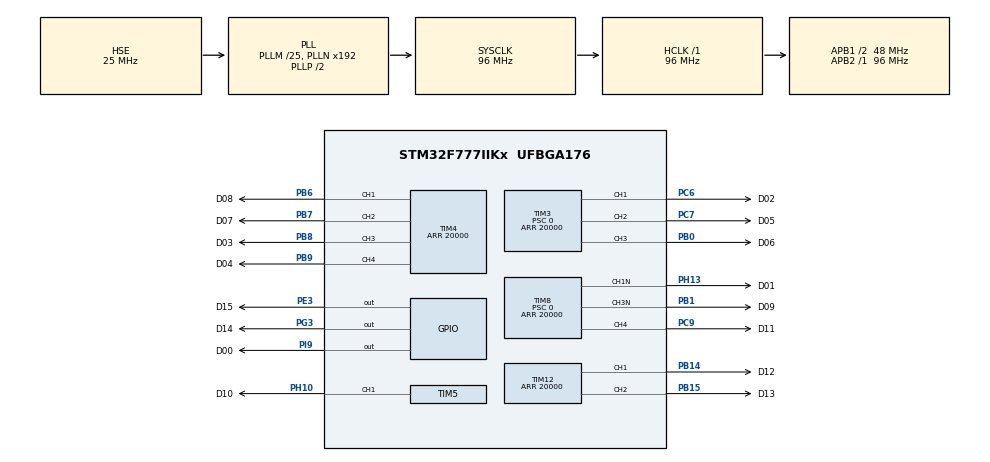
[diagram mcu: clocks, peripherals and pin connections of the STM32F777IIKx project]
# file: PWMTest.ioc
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Mcu.Family=STM32F7
Mcu.Name=STM32F777IIKx
Mcu.Package=UFBGA176
NVIC.PriorityGroup=NVIC_PRIORITYGROUP_4
PB0.GPIO_Label=D06
PB0.GPIO_Speed=GPIO_SPEED_FREQ_VERY_HIGH
PB0.Signal=S_TIM3_CH3
PB1.GPIO_Label=D09
PB1.GPIO_Speed=GPIO_SPEED_FREQ_VERY_HIGH
PB1.Mode=PWM Generation3 CH3N
PB1.Signal=TIM8_CH3N
PB14.GPIO_Label=D12
PB14.GPIO_Speed=GPIO_SPEED_FREQ_VERY_HIGH
PB14.Signal=S_TIM12_CH1
PB15.GPIO_Label=D13
PB15.GPIO_Speed=GPIO_SPEED_FREQ_VERY_HIGH
PB15.Signal=S_TIM12_CH2
PB6.GPIO_Label=D08
PB6.GPIO_Speed=GPIO_SPEED_FREQ_VERY_HIGH
PB6.Signal=S_TIM4_CH1
PB7.GPIO_Label=D07
PB7.GPIO_Speed=GPIO_SPEED_FREQ_VERY_HIGH
PB7.Signal=S_TIM4_CH2
PB8.GPIO_Label=D03
PB8.GPIO_Speed=GPIO_SPEED_FREQ_VERY_HIGH
PB8.Signal=S_TIM4_CH3
PB9.GPIO_Label=D04
PB9.GPIO_Speed=GPIO_SPEED_FREQ_VERY_HIGH
PB9.Signal=S_TIM4_CH4
PC6.GPIO_Label=D02
PC6.GPIO_Speed=GPIO_SPEED_FREQ_VERY_HIGH
PC6.Signal=S_TIM3_CH1
PC7.GPIO_Label=D05
PC7.GPIO_Speed=GPIO_SPEED_FREQ_VERY_HIGH
PC7.Signal=S_TIM3_CH2
PC9.GPIO_Label=D11
PC9.GPIO_Speed=GPIO_SPEED_FREQ_VERY_HIGH
PC9.Signal=S_TIM8_CH4
PE3.GPIO_Label=D15
PE3.GPIO_Speed=GPIO_SPEED_FREQ_VERY_HIGH
PE3.Signal=GPIO_Output
PG3.GPIO_Label=D14
PG3.GPIO_Speed=GPIO_SPEED_FREQ_VERY_HIGH
PG3.Signal=GPIO_Output
PH0/OSC_IN.Mode=HSE-External-Oscillator
PH0/OSC_IN.Signal=RCC_OSC_IN
PH1/OSC_OUT.Mode=HSE-External-Oscillator
PH1/OSC_OUT.Signal=RCC_OSC_OUT
PH10.GPIO_Label=D10
PH10.GPIO_Speed=GPIO_SPEED_FREQ_VERY_HIGH
PH10.Signal=S_TIM5_CH1
PH13.GPIO_Label=D01
PH13.GPIO_Speed=GPIO_SPEED_FREQ_VERY_HIGH
PH13.Mode=PWM Generation1 CH1N
PH13.Signal=TIM8_CH1N
PI9.GPIO_Label=D00
PI9.GPIO_Speed=GPIO_SPEED_FREQ_VERY_HIGH
PI9.Signal=GPIO_Output
ProjectManager.HeapSize=0x200
ProjectManager.StackSize=0x400
ProjectManager.TargetToolchain=STM32CubeIDE
RCC.AHBFreq_Value=96000000
RCC.APB1CLKDivider=RCC_HCLK_DIV2
RCC.APB1Freq_Value=48000000
RCC.APB1TimFreq_Value=96000000
RCC.APB2Freq_Value=96000000
RCC.APB2TimFreq_Value=96000000
RCC.CortexFreq_Value=96000000
RCC.HCLKFreq_Value=96000000
RCC.HSE_VALUE=25000000
RCC.HSI_VALUE=16000000
RCC.LSE_VALUE=32768
RCC.PLLM=25
RCC.PLLSourceVirtual=RCC_PLLSOURCE_HSE
RCC.SYSCLKFreq_VALUE=96000000
RCC.SYSCLKSource=RCC_SYSCLKSOURCE_PLLCLK
RCC.USBFreq_Value=96000000
RCC.VCOOutputFreq_Value=192000000
SH.S_TIM12_CH1.0=TIM12_CH1,PWM Generation1 CH1
SH.S_TIM12_CH2.0=TIM12_CH2,PWM Generation2 CH2
SH.S_TIM3_CH1.0=TIM3_CH1,PWM Generation1 CH1
SH.S_TIM3_CH2.0=TIM3_CH2,PWM Generation2 CH2
SH.S_TIM3_CH3.0=TIM3_CH3,PWM Generation3 CH3
SH.S_TIM4_CH1.0=TIM4_CH1,PWM Generation1 CH1
SH.S_TIM4_CH2.0=TIM4_CH2,PWM Generation2 CH2
SH.S_TIM4_CH3.0=TIM4_CH3,PWM Generation3 CH3
SH.S_TIM4_CH4.0=TIM4_CH4,PWM Generation4 CH4
SH.S_TIM5_CH1.0=TIM5_CH1,PWM Generation1 CH1
SH.S_TIM8_CH4.0=TIM8_CH4,PWM Generation4 CH4
TIM12.Channel-PWM\ Generation1\ CH1=TIM_CHANNEL_1
TIM12.Channel-PWM\ Generation2\ CH2=TIM_CHANNEL_2
TIM12.Period=20000
TIM12.Pulse-PWM\ Generation1\ CH1=13000
TIM12.Pulse-PWM\ Generation2\ CH2=14000
TIM3.AutoReloadPreload=TIM_AUTORELOAD_PRELOAD_DISABLE
TIM3.Channel-PWM\ Generation1\ CH1=TIM_CHANNEL_1
TIM3.Channel-PWM\ Generation2\ CH2=TIM_CHANNEL_2
TIM3.Channel-PWM\ Generation3\ CH3=TIM_CHANNEL_3
TIM3.Period=20000
TIM3.Prescaler=0
TIM3.Pulse-PWM\ Generation1\ CH1=3000
TIM3.Pulse-PWM\ Generation2\ CH2=6000
TIM3.Pulse-PWM\ Generation3\ CH3=7000
TIM4.Channel-PWM\ Generation1\ CH1=TIM_CHANNEL_1
TIM4.Channel-PWM\ Generation2\ CH2=TIM_CHANNEL_2
TIM4.Channel-PWM\ Generation3\ CH3=TIM_CHANNEL_3
TIM4.Channel-PWM\ Generation4\ CH4=TIM_CHANNEL_4
TIM4.Period=20000
TIM4.Pulse-PWM\ Generation1\ CH1=9000
TIM4.Pulse-PWM\ Generation2\ CH2=8000
TIM4.Pulse-PWM\ Generation3\ CH3=4000
TIM4.Pulse-PWM\ Generation4\ CH4=5000
TIM5.Channel-PWM\ Generation1\ CH1=TIM_CHANNEL_1
TIM5.Period=20000
TIM5.Pulse-PWM\ Generation1\ CH1=11000
TIM8.Channel-PWM\ Generation1\ CH1N=TIM_CHANNEL_1
TIM8.Channel-PWM\ Generation3\ CH3N=TIM_CHANNEL_3
TIM8.Channel-PWM\ Generation4\ CH4=TIM_CHANNEL_4
TIM8.Period=20000
TIM8.Prescaler=0
TIM8.Pulse-PWM\ Generation1\ CH1N=2000
TIM8.Pulse-PWM\ Generation3\ CH3N=10000
TIM8.Pulse-PWM\ Generation4\ CH4=12000
VP_TIM3_VS_ClockSourceINT.Mode=Internal
board=custom

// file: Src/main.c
/* USER CODE BEGIN Header */
/**
  ******************************************************************************
  * @file           : main.c
  * @brief          : Main program body
  ******************************************************************************
  ** This notice applies to any and all portions of this file
  * that are not between comment pairs USER CODE BEGIN and
  * USER CODE END. Other portions of this file, whether
  * inserted by the user or by software development tools
  * are owned by their respective copyright owners.
  *
  * COPYRIGHT(c) 2019 STMicroelectronics
  *
  * Redistribution and use in source and binary forms, with or without modification,
  * are permitted provided that the following conditions are met:
  *   1. Redistributions of source code must retain the above copyright notice,
  *      this list of conditions and the following disclaimer.
  *   2. Redistributions in binary form must reproduce the above copyright notice,
  *      this list of conditions and the following disclaimer in the documentation
  *      and/or other materials provided with the distribution.
  *   3. Neither the name of STMicroelectronics nor the names of its contributors
  *      may be used to endorse or promote products derived from this software
  *      without specific prior written permission.
  *
  * THIS SOFTWARE IS PROVIDED BY THE COPYRIGHT HOLDERS AND CONTRIBUTORS "AS IS"
  * AND ANY EXPRESS OR IMPLIED WARRANTIES, INCLUDING, BUT NOT LIMITED TO, THE
  * IMPLIED WARRANTIES OF MERCHANTABILITY AND FITNESS FOR A PARTICULAR PURPOSE ARE
  * DISCLAIMED. IN NO EVENT SHALL THE COPYRIGHT HOLDER OR CONTRIBUTORS BE LIABLE
  * FOR ANY DIRECT, INDIRECT, INCIDENTAL, SPECIAL, EXEMPLARY, OR CONSEQUENTIAL
  * DAMAGES (INCLUDING, BUT NOT LIMITED TO, PROCUREMENT OF SUBSTITUTE GOODS OR
  * SERVICES; LOSS OF USE, DATA, OR PROFITS; OR BUSINESS INTERRUPTION) HOWEVER
  * CAUSED AND ON ANY THEORY OF LIABILITY, WHETHER IN CONTRACT, STRICT LIABILITY,
  * OR TORT (INCLUDING NEGLIGENCE OR OTHERWISE) ARISING IN ANY WAY OUT OF THE USE
  * OF THIS SOFTWARE, EVEN IF ADVISED OF THE POSSIBILITY OF SUCH DAMAGE.
  *
  ******************************************************************************
  */
/* USER CODE END Header */

#include "main.h"

TIM_HandleTypeDef htim3;
TIM_HandleTypeDef htim4;
TIM_HandleTypeDef htim5;
TIM_HandleTypeDef htim8;
TIM_HandleTypeDef htim12;

void SystemClock_Config(void);
static void MX_GPIO_Init(void);
static void MX_TIM3_Init(void);
static void MX_TIM4_Init(void);
static void MX_TIM5_Init(void);
static void MX_TIM8_Init(void);
static void MX_TIM12_Init(void);

int main(void)
{

  /* MCU Configuration--------------------------------------------------------*/

  /* Reset of all peripherals, Initializes the Flash interface and the Systick. */
  HAL_Init();

  /* Configure the system clock */
  SystemClock_Config();

  /* Initialize all configured peripherals */
  MX_GPIO_Init();
  MX_TIM3_Init();
  MX_TIM4_Init();
  MX_TIM5_Init();
  MX_TIM8_Init();
  MX_TIM12_Init();
  /* USER CODE BEGIN 2 */

  HAL_TIM_PWM_Start(&htim3, TIM_CHANNEL_1);       //  D02
  HAL_TIM_PWM_Start(&htim3, TIM_CHANNEL_2);       //  D05
  HAL_TIM_PWM_Start(&htim3, TIM_CHANNEL_3);       //  D06

  HAL_TIM_PWM_Start(&htim4, TIM_CHANNEL_1);       //  D08
  HAL_TIM_PWM_Start(&htim4, TIM_CHANNEL_2);       //  D07
  HAL_TIM_PWM_Start(&htim4, TIM_CHANNEL_3);       //  D03
  HAL_TIM_PWM_Start(&htim4, TIM_CHANNEL_4);       //  D04

  HAL_TIM_PWM_Start(&htim5, TIM_CHANNEL_1);       //  D10

  HAL_TIMEx_PWMN_Start(&htim8, TIM_CHANNEL_1);    //  D01
  HAL_TIMEx_PWMN_Start(&htim8, TIM_CHANNEL_3);    //  D09
  HAL_TIM_PWM_Start(&htim8, TIM_CHANNEL_4);       //  D11

  HAL_TIM_PWM_Start(&htim12, TIM_CHANNEL_1);      //  D12
  HAL_TIM_PWM_Start(&htim12, TIM_CHANNEL_2);      //  D13

  /* USER CODE END 2 */

  /* Infinite loop */
  while (1)
  {

  }
}

void SystemClock_Config(void)
{
  RCC_OscInitTypeDef RCC_OscInitStruct = {0};
  RCC_ClkInitTypeDef RCC_ClkInitStruct = {0};

  /** Configure the main internal regulator output voltage
  */
  __HAL_RCC_PWR_CLK_ENABLE();
  __HAL_PWR_VOLTAGESCALING_CONFIG(PWR_REGULATOR_VOLTAGE_SCALE3);
  /** Initializes the CPU, AHB and APB busses clocks
  */
  RCC_OscInitStruct.OscillatorType = RCC_OSCILLATORTYPE_HSE;
  RCC_OscInitStruct.HSEState = RCC_HSE_ON;
  RCC_OscInitStruct.PLL.PLLState = RCC_PLL_ON;
  RCC_OscInitStruct.PLL.PLLSource = RCC_PLLSOURCE_HSE;
  RCC_OscInitStruct.PLL.PLLM = 25;
  RCC_OscInitStruct.PLL.PLLN = 192;
  RCC_OscInitStruct.PLL.PLLP = RCC_PLLP_DIV2;
  RCC_OscInitStruct.PLL.PLLQ = 2;
  if (HAL_RCC_OscConfig(&RCC_OscInitStruct) != HAL_OK)
  {
    Error_Handler();
  }
  /** Activate the Over-Drive mode
  */
  if (HAL_PWREx_EnableOverDrive() != HAL_OK)
  {
    Error_Handler();
  }
  /** Initializes the CPU, AHB and APB busses clocks
  */
  RCC_ClkInitStruct.ClockType = RCC_CLOCKTYPE_HCLK|RCC_CLOCKTYPE_SYSCLK
                              |RCC_CLOCKTYPE_PCLK1|RCC_CLOCKTYPE_PCLK2;
  RCC_ClkInitStruct.SYSCLKSource = RCC_SYSCLKSOURCE_PLLCLK;
  RCC_ClkInitStruct.AHBCLKDivider = RCC_SYSCLK_DIV1;
  RCC_ClkInitStruct.APB1CLKDivider = RCC_HCLK_DIV2;
  RCC_ClkInitStruct.APB2CLKDivider = RCC_HCLK_DIV1;

  if (HAL_RCC_ClockConfig(&RCC_ClkInitStruct, FLASH_LATENCY_3) != HAL_OK)
  {
    Error_Handler();
  }
}

static void MX_TIM3_Init(void)
{

  TIM_ClockConfigTypeDef sClockSourceConfig = {0};
  TIM_MasterConfigTypeDef sMasterConfig = {0};
  TIM_OC_InitTypeDef sConfigOC = {0};

  htim3.Instance = TIM3;
  htim3.Init.Prescaler = 0;
  htim3.Init.CounterMode = TIM_COUNTERMODE_UP;
  htim3.Init.Period = 20000;
  htim3.Init.ClockDivision = TIM_CLOCKDIVISION_DIV1;
  htim3.Init.AutoReloadPreload = TIM_AUTORELOAD_PRELOAD_DISABLE;
  if (HAL_TIM_Base_Init(&htim3) != HAL_OK)
  {
    Error_Handler();
  }
  sClockSourceConfig.ClockSource = TIM_CLOCKSOURCE_INTERNAL;
  if (HAL_TIM_ConfigClockSource(&htim3, &sClockSourceConfig) != HAL_OK)
  {
    Error_Handler();
  }
  if (HAL_TIM_PWM_Init(&htim3) != HAL_OK)
  {
    Error_Handler();
  }
  sMasterConfig.MasterOutputTrigger = TIM_TRGO_RESET;
  sMasterConfig.MasterSlaveMode = TIM_MASTERSLAVEMODE_DISABLE;
  if (HAL_TIMEx_MasterConfigSynchronization(&htim3, &sMasterConfig) != HAL_OK)
  {
    Error_Handler();
  }
  sConfigOC.OCMode = TIM_OCMODE_PWM1;
  sConfigOC.Pulse = 3000;
  sConfigOC.OCPolarity = TIM_OCPOLARITY_HIGH;
  sConfigOC.OCFastMode = TIM_OCFAST_DISABLE;
  if (HAL_TIM_PWM_ConfigChannel(&htim3, &sConfigOC, TIM_CHANNEL_1) != HAL_OK)
  {
    Error_Handler();
  }
  sConfigOC.Pulse = 6000;
  if (HAL_TIM_PWM_ConfigChannel(&htim3, &sConfigOC, TIM_CHANNEL_2) != HAL_OK)
  {
    Error_Handler();
  }
  sConfigOC.Pulse = 7000;
  if (HAL_TIM_PWM_ConfigChannel(&htim3, &sConfigOC, TIM_CHANNEL_3) != HAL_OK)
  {
    Error_Handler();
  }
  HAL_TIM_MspPostInit(&htim3);

}

static void MX_TIM4_Init(void)
{

  TIM_MasterConfigTypeDef sMasterConfig = {0};
  TIM_OC_InitTypeDef sConfigOC = {0};

  htim4.Instance = TIM4;
  htim4.Init.Prescaler = 0;
  htim4.Init.CounterMode = TIM_COUNTERMODE_UP;
  htim4.Init.Period = 20000;
  htim4.Init.ClockDivision = TIM_CLOCKDIVISION_DIV1;
  htim4.Init.AutoReloadPreload = TIM_AUTORELOAD_PRELOAD_DISABLE;
  if (HAL_TIM_PWM_Init(&htim4) != HAL_OK)
  {
    Error_Handler();
  }
  sMasterConfig.MasterOutputTrigger = TIM_TRGO_RESET;
  sMasterConfig.MasterSlaveMode = TIM_MASTERSLAVEMODE_DISABLE;
  if (HAL_TIMEx_MasterConfigSynchronization(&htim4, &sMasterConfig) != HAL_OK)
  {
    Error_Handler();
  }
  sConfigOC.OCMode = TIM_OCMODE_PWM1;
  sConfigOC.Pulse = 9000;
  sConfigOC.OCPolarity = TIM_OCPOLARITY_HIGH;
  sConfigOC.OCFastMode = TIM_OCFAST_DISABLE;
  if (HAL_TIM_PWM_ConfigChannel(&htim4, &sConfigOC, TIM_CHANNEL_1) != HAL_OK)
  {
    Error_Handler();
  }
  sConfigOC.Pulse = 8000;
  if (HAL_TIM_PWM_ConfigChannel(&htim4, &sConfigOC, TIM_CHANNEL_2) != HAL_OK)
  {
    Error_Handler();
  }
  sConfigOC.Pulse = 4000;
  if (HAL_TIM_PWM_ConfigChannel(&htim4, &sConfigOC, TIM_CHANNEL_3) != HAL_OK)
  {
    Error_Handler();
  }
  sConfigOC.Pulse = 5000;
  if (HAL_TIM_PWM_ConfigChannel(&htim4, &sConfigOC, TIM_CHANNEL_4) != HAL_OK)
  {
    Error_Handler();
  }
  HAL_TIM_MspPostInit(&htim4);

}

static void MX_TIM5_Init(void)
{

  TIM_MasterConfigTypeDef sMasterConfig = {0};
  TIM_OC_InitTypeDef sConfigOC = {0};

  htim5.Instance = TIM5;
  htim5.Init.Prescaler = 0;
  htim5.Init.CounterMode = TIM_COUNTERMODE_UP;
  htim5.Init.Period = 20000;
  htim5.Init.ClockDivision = TIM_CLOCKDIVISION_DIV1;
  htim5.Init.AutoReloadPreload = TIM_AUTORELOAD_PRELOAD_DISABLE;
  if (HAL_TIM_PWM_Init(&htim5) != HAL_OK)
  {
    Error_Handler();
  }
  sMasterConfig.MasterOutputTrigger = TIM_TRGO_RESET;
  sMasterConfig.MasterSlaveMode = TIM_MASTERSLAVEMODE_DISABLE;
  if (HAL_TIMEx_MasterConfigSynchronization(&htim5, &sMasterConfig) != HAL_OK)
  {
    Error_Handler();
  }
  sConfigOC.OCMode = TIM_OCMODE_PWM1;
  sConfigOC.Pulse = 11000;
  sConfigOC.OCPolarity = TIM_OCPOLARITY_HIGH;
  sConfigOC.OCFastMode = TIM_OCFAST_DISABLE;
  if (HAL_TIM_PWM_ConfigChannel(&htim5, &sConfigOC, TIM_CHANNEL_1) != HAL_OK)
  {
    Error_Handler();
  }
  HAL_TIM_MspPostInit(&htim5);

}

static void MX_TIM8_Init(void)
{

  TIM_MasterConfigTypeDef sMasterConfig = {0};
  TIM_OC_InitTypeDef sConfigOC = {0};
  TIM_BreakDeadTimeConfigTypeDef sBreakDeadTimeConfig = {0};

  htim8.Instance = TIM8;
  htim8.Init.Prescaler = 0;
  htim8.Init.CounterMode = TIM_COUNTERMODE_UP;
  htim8.Init.Period = 20000;
  htim8.Init.ClockDivision = TIM_CLOCKDIVISION_DIV1;
  htim8.Init.RepetitionCounter = 0;
  htim8.Init.AutoReloadPreload = TIM_AUTORELOAD_PRELOAD_DISABLE;
  if (HAL_TIM_PWM_Init(&htim8) != HAL_OK)
  {
    Error_Handler();
  }
  sMasterConfig.MasterOutputTrigger = TIM_TRGO_RESET;
  sMasterConfig.MasterOutputTrigger2 = TIM_TRGO2_RESET;
  sMasterConfig.MasterSlaveMode = TIM_MASTERSLAVEMODE_DISABLE;
  if (HAL_TIMEx_MasterConfigSynchronization(&htim8, &sMasterConfig) != HAL_OK)
  {
    Error_Handler();
  }
  sConfigOC.OCMode = TIM_OCMODE_PWM1;
  sConfigOC.Pulse = 2000;
  sConfigOC.OCPolarity = TIM_OCPOLARITY_HIGH;
  sConfigOC.OCNPolarity = TIM_OCNPOLARITY_HIGH;
  sConfigOC.OCFastMode = TIM_OCFAST_DISABLE;
  sConfigOC.OCIdleState = TIM_OCIDLESTATE_RESET;
  sConfigOC.OCNIdleState = TIM_OCNIDLESTATE_RESET;
  if (HAL_TIM_PWM_ConfigChannel(&htim8, &sConfigOC, TIM_CHANNEL_1) != HAL_OK)
  {
    Error_Handler();
  }
  sConfigOC.Pulse = 10000;
  if (HAL_TIM_PWM_ConfigChannel(&htim8, &sConfigOC, TIM_CHANNEL_3) != HAL_OK)
  {
    Error_Handler();
  }
  sConfigOC.Pulse = 12000;
  if (HAL_TIM_PWM_ConfigChannel(&htim8, &sConfigOC, TIM_CHANNEL_4) != HAL_OK)
  {
    Error_Handler();
  }
  sBreakDeadTimeConfig.OffStateRunMode = TIM_OSSR_DISABLE;
  sBreakDeadTimeConfig.OffStateIDLEMode = TIM_OSSI_DISABLE;
  sBreakDeadTimeConfig.LockLevel = TIM_LOCKLEVEL_OFF;
  sBreakDeadTimeConfig.DeadTime = 0;
  sBreakDeadTimeConfig.BreakState = TIM_BREAK_DISABLE;
  sBreakDeadTimeConfig.BreakPolarity = TIM_BREAKPOLARITY_HIGH;
  sBreakDeadTimeConfig.BreakFilter = 0;
  sBreakDeadTimeConfig.Break2State = TIM_BREAK2_DISABLE;
  sBreakDeadTimeConfig.Break2Polarity = TIM_BREAK2POLARITY_HIGH;
  sBreakDeadTimeConfig.Break2Filter = 0;
  sBreakDeadTimeConfig.AutomaticOutput = TIM_AUTOMATICOUTPUT_DISABLE;
  if (HAL_TIMEx_ConfigBreakDeadTime(&htim8, &sBreakDeadTimeConfig) != HAL_OK)
  {
    Error_Handler();
  }
  HAL_TIM_MspPostInit(&htim8);

}

static void MX_TIM12_Init(void)
{

  TIM_OC_InitTypeDef sConfigOC = {0};

  htim12.Instance = TIM12;
  htim12.Init.Prescaler = 0;
  htim12.Init.CounterMode = TIM_COUNTERMODE_UP;
  htim12.Init.Period = 20000;
  htim12.Init.ClockDivision = TIM_CLOCKDIVISION_DIV1;
  htim12.Init.AutoReloadPreload = TIM_AUTORELOAD_PRELOAD_DISABLE;
  if (HAL_TIM_PWM_Init(&htim12) != HAL_OK)
  {
    Error_Handler();
  }
  sConfigOC.OCMode = TIM_OCMODE_PWM1;
  sConfigOC.Pulse = 13000;
  sConfigOC.OCPolarity = TIM_OCPOLARITY_HIGH;
  sConfigOC.OCFastMode = TIM_OCFAST_DISABLE;
  if (HAL_TIM_PWM_ConfigChannel(&htim12, &sConfigOC, TIM_CHANNEL_1) != HAL_OK)
  {
    Error_Handler();
  }
  sConfigOC.Pulse = 14000;
  if (HAL_TIM_PWM_ConfigChannel(&htim12, &sConfigOC, TIM_CHANNEL_2) != HAL_OK)
  {
    Error_Handler();
  }
  HAL_TIM_MspPostInit(&htim12);

}

static void MX_GPIO_Init(void)
{
  GPIO_InitTypeDef GPIO_InitStruct = {0};

  /* GPIO Ports Clock Enable */
  __HAL_RCC_GPIOE_CLK_ENABLE();
  __HAL_RCC_GPIOB_CLK_ENABLE();
  __HAL_RCC_GPIOI_CLK_ENABLE();
  __HAL_RCC_GPIOH_CLK_ENABLE();
  __HAL_RCC_GPIOC_CLK_ENABLE();
  __HAL_RCC_GPIOG_CLK_ENABLE();

  /*Configure GPIO pin Output Level */
  HAL_GPIO_WritePin(D15_GPIO_Port, D15_Pin, GPIO_PIN_RESET);

  /*Configure GPIO pin Output Level */
  HAL_GPIO_WritePin(D00_GPIO_Port, D00_Pin, GPIO_PIN_RESET);

  /*Configure GPIO pin Output Level */
  HAL_GPIO_WritePin(D14_GPIO_Port, D14_Pin, GPIO_PIN_RESET);

  /*Configure GPIO pin : D15_Pin */
  GPIO_InitStruct.Pin = D15_Pin;
  GPIO_InitStruct.Mode = GPIO_MODE_OUTPUT_PP;
  GPIO_InitStruct.Pull = GPIO_NOPULL;
  GPIO_InitStruct.Speed = GPIO_SPEED_FREQ_VERY_HIGH;
  HAL_GPIO_Init(D15_GPIO_Port, &GPIO_InitStruct);

  /*Configure GPIO pin : D00_Pin */
  GPIO_InitStruct.Pin = D00_Pin;
  GPIO_InitStruct.Mode = GPIO_MODE_OUTPUT_PP;
  GPIO_InitStruct.Pull = GPIO_NOPULL;
  GPIO_InitStruct.Speed = GPIO_SPEED_FREQ_VERY_HIGH;
  HAL_GPIO_Init(D00_GPIO_Port, &GPIO_InitStruct);

  /*Configure GPIO pin : D14_Pin */
  GPIO_InitStruct.Pin = D14_Pin;
  GPIO_InitStruct.Mode = GPIO_MODE_OUTPUT_PP;
  GPIO_InitStruct.Pull = GPIO_NOPULL;
  GPIO_InitStruct.Speed = GPIO_SPEED_FREQ_VERY_HIGH;
  HAL_GPIO_Init(D14_GPIO_Port, &GPIO_InitStruct);

}

void Error_Handler(void)
{
}

/************************ (C) COPYRIGHT STMicroelectronics *****END OF FILE****/
